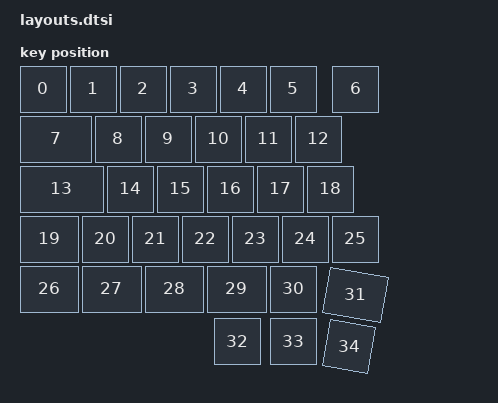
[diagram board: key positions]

#include <physical_layouts.dtsi>
/ {
    physical_layout0: physical_layout0 {
        compatible = "zmk,physical-layout";
        display-name = "Layout";
        keys
            = <&key_physical_attrs 100 100 (-50) 0 0 0 0>
			,<&key_physical_attrs 100 100 50 0 0 0 0>
			,<&key_physical_attrs 100 100 150 0 0 0 0>
			,<&key_physical_attrs 100 100 250 0 0 0 0>
			,<&key_physical_attrs 100 100 350 0 0 0 0>
			,<&key_physical_attrs 100 100 450 0 0 0 0>
			,<&key_physical_attrs 100 100 575 0 0 0 0>
			,<&key_physical_attrs 150 100 (-50) 100 0 0 0>
			,<&key_physical_attrs 100 100 100 100 0 0 0>
			,<&key_physical_attrs 100 100 200 100 0 0 0>
			,<&key_physical_attrs 100 100 300 100 0 0 0>
			,<&key_physical_attrs 100 100 400 100 0 0 0>
			,<&key_physical_attrs 100 100 500 100 0 0 0>
			,<&key_physical_attrs 175 100 (-50) 200 0 0 0>
			,<&key_physical_attrs 100 100 125 200 0 0 0>
			,<&key_physical_attrs 100 100 225 200 0 0 0>
			,<&key_physical_attrs 100 100 325 200 0 0 0>
			,<&key_physical_attrs 100 100 425 200 0 0 0>
			,<&key_physical_attrs 100 100 525 200 0 0 0>
			,<&key_physical_attrs 125 100 (-50) 300 0 0 0>
			,<&key_physical_attrs 100 100 75 300 0 0 0>
			,<&key_physical_attrs 100 100 175 300 0 0 0>
			,<&key_physical_attrs 100 100 275 300 0 0 0>
			,<&key_physical_attrs 100 100 375 300 0 0 0>
			,<&key_physical_attrs 100 100 475 300 0 0 0>
			,<&key_physical_attrs 100 100 575 300 0 0 0>
			,<&key_physical_attrs 125 100 (-50) 400 0 0 0>
			,<&key_physical_attrs 125 100 75 400 0 0 0>
			,<&key_physical_attrs 125 100 200 400 0 0 0>
			,<&key_physical_attrs 125 100 325 400 0 0 0>
			,<&key_physical_attrs 100 100 450 400 0 0 0>
			,<&key_physical_attrs 125 100 572 402 1000 572 402>
			,<&key_physical_attrs 100 100 338 505 0 0 0>
			,<&key_physical_attrs 100 100 450 505 0 0 0>
			,<&key_physical_attrs 100 100 572 507 1000 572 507>
            ;
    };
};
    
